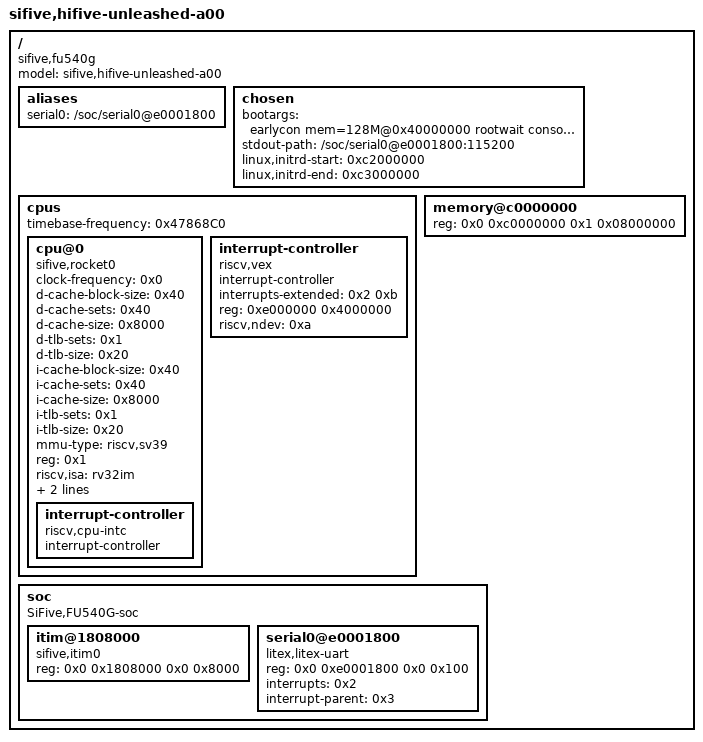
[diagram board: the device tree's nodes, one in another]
/dts-v1/;

/ {
	#address-cells = <0x2>;
	#size-cells = <0x2>;
	compatible = "sifive,fu540g", "sifive,fu500";
	model = "sifive,hifive-unleashed-a00";

	aliases {
		serial0 = "/soc/serial0@e0001800";
	};

	chosen {
		bootargs = "earlycon mem=128M@0x40000000 rootwait console=ttyLX0,115200 root=/dev/ram0 init=/sbin/init";
		stdout-path = "/soc/serial0@e0001800:115200";
		linux,initrd-start = <0xc2000000>;
		linux,initrd-end = <0xc3000000>;
	};

	cpus {
		#address-cells = <0x1>;
		#size-cells = <0x0>;
		timebase-frequency = <0x47868C0>;

		cpu@0 {
			clock-frequency = <0x0>;
			compatible = "sifive,rocket0", "riscv";
			d-cache-block-size = <0x40>;
			d-cache-sets = <0x40>;
			d-cache-size = <0x8000>;
			d-tlb-sets = <0x1>;
			d-tlb-size = <0x20>;
			device_type = "cpu";
			i-cache-block-size = <0x40>;
			i-cache-sets = <0x40>;
			i-cache-size = <0x8000>;
			i-tlb-sets = <0x1>;
			i-tlb-size = <0x20>;
			mmu-type = "riscv,sv39";
			reg = <0x1>;
			riscv,isa = "rv32im";
			sifive,itim = <0x1>;
			status = "okay";
			tlb-split;

			interrupt-controller {
				#interrupt-cells = <0x1>;
				compatible = "riscv,cpu-intc";
				interrupt-controller;
				phandle = <0x2>;
			};
		};

		interrupt-controller {
			#address-cells = <0x0>;
			#interrupt-cells = <0x1>;
			compatible = "riscv,vex";
			interrupt-controller;
			interrupts-extended = <0x2 0xb>;
			reg = <0xe000000 0x4000000>;
			riscv,ndev = <0xa>;
			phandle = <0x3>;
		};
	};

	memory@c0000000 {
		device_type = "memory";
		reg = <0x0 0xc0000000 0x1 0x08000000>;
	};

	soc {
		#address-cells = <0x2>;
		#size-cells = <0x2>;
		compatible = "SiFive,FU540G-soc", "fu500-soc", "sifive-soc", "simple-bus";
		ranges;

		itim@1808000 {
			compatible = "sifive,itim0";
			reg = <0x0 0x1808000 0x0 0x8000>;
			reg-names = "mem";
			linux,phandle = <0x1>;
			phandle = <0x1>;
		};

		serial0@e0001800 {
			device_type = "serial";
			compatible = "litex,litex-uart";
			reg = <0x0 0xe0001800 0x0 0x100>;
			interrupts = <0x2>;
			interrupt-parent = <0x3>;
		};
	};
};
